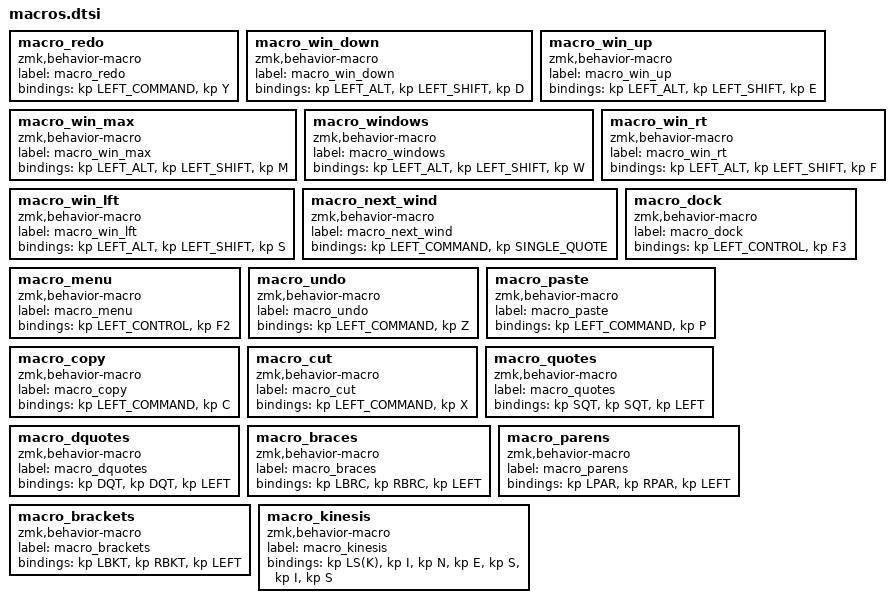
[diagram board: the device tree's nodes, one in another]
macro_redo: macro_redo{
compatible = "zmk,behavior-macro";
label = "macro_redo";
#binding-cells = <0>;
bindings = <&kp LEFT_COMMAND>, <&kp Y>;
};
macro_win_down: macro_win_down{
compatible = "zmk,behavior-macro";
label = "macro_win_down";
#binding-cells = <0>;
bindings = <&kp LEFT_ALT>, <&kp LEFT_SHIFT>, <&kp D>;
};
macro_win_up: macro_win_up{
compatible = "zmk,behavior-macro";
label = "macro_win_up";
#binding-cells = <0>;
bindings = <&kp LEFT_ALT>, <&kp LEFT_SHIFT>, <&kp E>;
};
macro_win_max: macro_win_max{
compatible = "zmk,behavior-macro";
label = "macro_win_max";
#binding-cells = <0>;
bindings = <&kp LEFT_ALT>, <&kp LEFT_SHIFT>, <&kp M>;
};
macro_windows: macro_windows{
compatible = "zmk,behavior-macro";
label = "macro_windows";
#binding-cells = <0>;
bindings = <&kp LEFT_ALT>, <&kp LEFT_SHIFT>, <&kp W>;
};
macro_win_rt: macro_win_rt{
compatible = "zmk,behavior-macro";
label = "macro_win_rt";
#binding-cells = <0>;
bindings = <&kp LEFT_ALT>, <&kp LEFT_SHIFT>, <&kp F>;
};
macro_win_lft: macro_win_lft{
compatible = "zmk,behavior-macro";
label = "macro_win_lft";
#binding-cells = <0>;
bindings = <&kp LEFT_ALT>, <&kp LEFT_SHIFT>, <&kp S>;
};
macro_next_wind: macro_next_wind{
compatible = "zmk,behavior-macro";
label = "macro_next_wind";
#binding-cells = <0>;
bindings = <&kp LEFT_COMMAND>, <&kp SINGLE_QUOTE>;
};
macro_dock: macro_dock{
compatible = "zmk,behavior-macro";
label = "macro_dock";
#binding-cells = <0>;
bindings = <&kp LEFT_CONTROL>, <&kp F3>;
};
macro_menu: macro_menu{
compatible = "zmk,behavior-macro";
label = "macro_menu";
#binding-cells = <0>;
bindings = <&kp LEFT_CONTROL>, <&kp F2>;
};
macro_undo: macro_undo{
compatible = "zmk,behavior-macro";
label = "macro_undo";
#binding-cells = <0>;
bindings = <&kp LEFT_COMMAND>, <&kp Z>;
};
macro_paste: macro_paste{
compatible = "zmk,behavior-macro";
label = "macro_paste";
#binding-cells = <0>;
bindings = <&kp LEFT_COMMAND>, <&kp P>;
};
macro_copy: macro_copy{
compatible = "zmk,behavior-macro";
label = "macro_copy";
#binding-cells = <0>;
bindings = <&kp LEFT_COMMAND>, <&kp C>;
};
macro_cut: macro_cut{
compatible = "zmk,behavior-macro";
label = "macro_cut";
#binding-cells = <0>;
bindings = <&kp LEFT_COMMAND>, <&kp X>;
};
macro_quotes: macro_quotes{
compatible = "zmk,behavior-macro";
label = "macro_quotes";
#binding-cells = <0>;
bindings = <&kp SQT>, <&kp SQT>, <&kp LEFT>;
};
macro_dquotes: macro_dquotes{
compatible = "zmk,behavior-macro";
label = "macro_dquotes";
#binding-cells = <0>;
bindings = <&kp DQT>, <&kp DQT>, <&kp LEFT>;
};
macro_braces: macro_braces{
compatible = "zmk,behavior-macro";
label = "macro_braces";
#binding-cells = <0>;
bindings = <&kp LBRC>, <&kp RBRC>, <&kp LEFT>;
};
macro_parens: macro_parens{
compatible = "zmk,behavior-macro";
label = "macro_parens";
#binding-cells = <0>;
bindings = <&kp LPAR>, <&kp RPAR>, <&kp LEFT>;
};
macro_brackets: macro_brackets{
compatible = "zmk,behavior-macro";
label = "macro_brackets";
#binding-cells = <0>;
bindings = <&kp LBKT>, <&kp RBKT>, <&kp LEFT>;
};
macro_kinesis: macro_kinesis{
compatible = "zmk,behavior-macro";
label = "macro_kinesis";
#binding-cells = <0>;
bindings = <&kp LS(K)>, <&kp I>, <&kp N>, <&kp E>, <&kp S>, <&kp I>, <&kp S>;
};
macro_parens: macro_parens{
compatible = "zmk,behavior-macro";
label = "macro_parens";
#binding-cells = <0>;
bindings = <&kp LPAR>, <&kp RPAR>, <&kp LEFT>;
};
macro_brackets: macro_brackets{
compatible = "zmk,behavior-macro";
label = "macro_brackets";
#binding-cells = <0>;
bindings = <&kp LBKT>, <&kp RBKT>, <&kp LEFT>;
};
macro_kinesis: macro_kinesis{
compatible = "zmk,behavior-macro";
label = "macro_kinesis";
#binding-cells = <0>;
bindings = <&kp LS(K)>, <&kp I>, <&kp N>, <&kp E>, <&kp S>, <&kp I>, <&kp S>;
};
